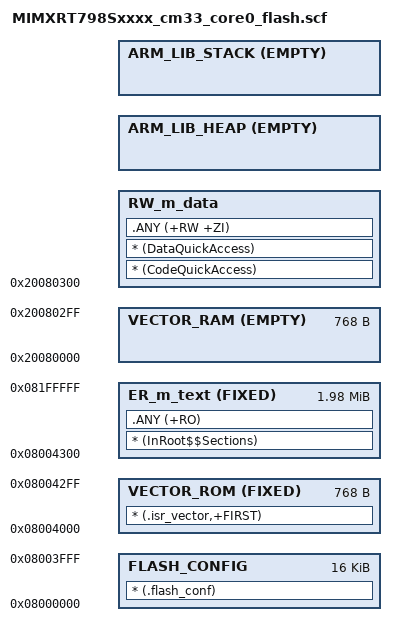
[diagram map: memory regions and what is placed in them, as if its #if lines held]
#!armclang --target=arm-arm-none-eabi -march=armv8-m.main -E -x c
/*
** ###################################################################
**     Processors:          MIMXRT798SGAWAR_cm33_core0
**                          MIMXRT798SGFOA_cm33_core0
**
**     Compiler:            Keil ARM C/C++ Compiler
**     Reference manual:    iMXRT700RM Rev.1, 06/2023
**     Version:             rev. 1.0, 2022-08-01
**     Build:               b231012
**
**     Abstract:
**         Linker file for the Keil ARM C/C++ Compiler
**
**     Copyright 2016 Freescale Semiconductor, Inc.
**     Copyright 2016-2023 NXP
**     SPDX-License-Identifier: BSD-3-Clause
**
**     http:                 www.nxp.com
**     mail:                 support@nxp.com
**
** ###################################################################
*/


/* Sizes */
#if (defined(__stack_size__))
  #define Stack_Size                   __stack_size__
#else
  #define Stack_Size                   0x0400
#endif

#if (defined(__heap_size__))
  #define Heap_Size                    __heap_size__
#else
  #define Heap_Size                    0x0400
#endif

/* The SRAM region [0x0-0x7FFFF] is reserved for Non-cached shared memory between M33 and DSP. */

#if (defined(__ram_vector_table__))
  #define __ram_vector_table_size__    0x00000300
#else
  #define __ram_vector_table_size__    0x00000000
#endif

#define  m_interrupts_start            0x08004000
#define  m_interrupts_size             0x00000300

#define  m_text_start                  0x08004300
#define  m_text_size                   0x001FBD00

#define m_interrupts_ram_start         0x20080000
#define m_interrupts_ram_size          __ram_vector_table_size__

#define  m_data_start                  (m_interrupts_ram_start + m_interrupts_ram_size)
#define  m_data_size                   (0x00280000 - m_interrupts_ram_size)

#define  m_boot_flash_conf_start       0x08000000

LR_m_flash_conf m_boot_flash_conf_start m_interrupts_start-m_boot_flash_conf_start {
  FLASH_CONFIG m_boot_flash_conf_start m_interrupts_start-m_boot_flash_conf_start{ ; load address = execution address
    * (.flash_conf)
  }
}

LR_m_interrupts m_interrupts_start m_text_start+m_text_size-m_interrupts_start {
  VECTOR_ROM m_interrupts_start FIXED m_interrupts_size { ; load address = execution address
    * (.isr_vector,+FIRST)
  }

  ER_m_text m_text_start FIXED m_text_size { ; load address = execution address
    * (InRoot$$Sections)
    .ANY (+RO)
  }
#if (defined(__ram_vector_table__))
  VECTOR_RAM m_interrupts_ram_start EMPTY m_interrupts_ram_size {
  }
#else
  VECTOR_RAM m_interrupts_start EMPTY 0 {
  }
#endif
  RW_m_data m_data_start ALIGN 4 m_data_size-Stack_Size-Heap_Size { ; RW data
    * (CodeQuickAccess)
    * (DataQuickAccess)
    .ANY (+RW +ZI)
  }

  ARM_LIB_HEAP +0 EMPTY Heap_Size {    ; Heap region growing up
  }
  ARM_LIB_STACK m_data_start+m_data_size EMPTY -Stack_Size { ; Stack region growing down
  }
}
